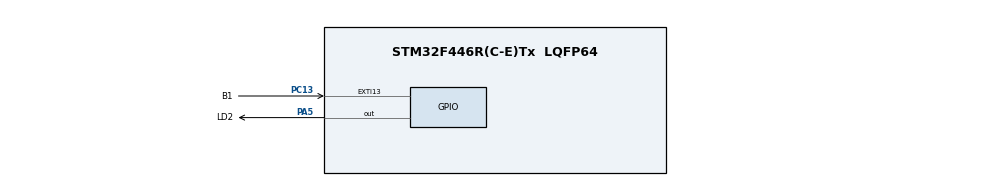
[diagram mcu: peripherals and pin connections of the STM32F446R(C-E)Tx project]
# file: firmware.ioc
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Mcu.Family=STM32F4
Mcu.Name=STM32F446R(C-E)Tx
Mcu.Package=LQFP64
NVIC.EXTI15_10_IRQn=true\:0\:0\:false\:false\:true\:true\:true\:true
NVIC.PriorityGroup=NVIC_PRIORITYGROUP_4
PA5.GPIO_Label=LD2
PA5.Signal=GPIO_Output
PA13.Mode=Serial_Wire
PA13.Signal=SYS_JTMS-SWDIO
PA14.Mode=Serial_Wire
PA14.Signal=SYS_JTCK-SWCLK
PC13.GPIO_Label=B1
PC13.GPIO_ModeDefaultEXTI=GPIO_MODE_IT_FALLING
PC13.GPIO_PuPd=GPIO_NOPULL
PC13.Signal=GPXTI13
PH0-OSC_IN.Mode=HSE-External-Clock-Source
PH0-OSC_IN.Signal=RCC_OSC_IN
PH1-OSC_OUT.Mode=HSE-External-Clock-Source
PH1-OSC_OUT.Signal=RCC_OSC_OUT
ProjectManager.HeapSize=0x200
ProjectManager.StackSize=0x400
ProjectManager.TargetToolchain=STM32CubeIDE
RCC.CortexFreq_Value=16000000
RCC.USBFreq_Value=96000000
RCC.VCOOutputFreq_Value=192000000
SYS.DebugMode=Serial_Wire
board=custom

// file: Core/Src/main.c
/* USER CODE BEGIN Header */
/**
  ******************************************************************************
  * @file           : main.c
  * @brief          : Main program body
  ******************************************************************************
  * @attention
  *
  * Copyright (c) 2026 STMicroelectronics.
  * All rights reserved.
  *
  * This software is licensed under terms that can be found in the LICENSE file
  * in the root directory of this software component.
  * If no LICENSE file comes with this software, it is provided AS-IS.
  *
  ******************************************************************************
  */
/* USER CODE END Header */
#include "main.h"

/* USER CODE BEGIN Includes */
#include "level_check.h"
#include "status_LEDs.h"
#include "pump_control.h"
#include "dose_calc.h"
/* USER CODE END Includes */

void SystemClock_Config(void);
static void MX_GPIO_Init(void);

int main(void)
{

  /* MCU Configuration--------------------------------------------------------*/

  /* Reset of all peripherals, Initializes the Flash interface and the Systick. */
  HAL_Init();

  /* Configure the system clock */
  SystemClock_Config();

  /* Initialize all configured peripherals */
  MX_GPIO_Init();
  /* USER CODE BEGIN 2 */
  level_check_init();
  status_leds_init();
  pump_control_init();
  /* USER CODE END 2 */

  /* Infinite loop */
  while (1)
  {
	  // latches on once the level drops below the refill mark, and only
	  // clears once the tank is actually topped back up to the full mark -
	  // so yellow stays on for the whole refill cycle, not just until the
	  // level ticks back above the refill switch.
	  static bool needs_refill = false;

	  if (tank_is_full())
	  {
		  needs_refill = false;
	  }
	  else if (tank_below_refill())
	  {
		  needs_refill = true;
	  }

	  tank_state_t tank_state;
	  if (tank_is_low())
	  {
		  tank_state = TANK_LOW;
	  }
	  else if (needs_refill)
	  {
		  tank_state = TANK_REFILL;
	  }
	  else
	  {
		  tank_state = TANK_FULL;
	  }
	  tank_leds_set(tank_state);

	  bot1_leds_set(bot1_is_empty() ? BOT_EMPTY : BOT_FULL);
	  bot2_leds_set(bot2_is_empty() ? BOT_EMPTY : BOT_FULL);
	  bot3_leds_set(bot3_is_empty() ? BOT_EMPTY : BOT_FULL);
	  bot4_leds_set(bot4_is_empty() ? BOT_EMPTY : BOT_FULL);

	  pump_control_update();

	  // bench characterization: B1 press starts a test dose on the next
	  // pump in rotation, cycling A->B->C->D->A... so all 4 can be run
	  // without reflashing between them. debounced the same way as the
	  // level switches - sampled once per 50 ms loop pass. TODO: once
	  // dosing is closed-loop, remap B1 to an e-stop instead.
	  static dose_content_t next_test_pump = DOSE_CAL_NITRATE;
	  static bool button_stable = false;
	  static bool button_candidate = false;
	  static uint8_t button_count = 0;

	  bool button_raw = (HAL_GPIO_ReadPin(B1_GPIO_Port, B1_Pin) == GPIO_PIN_RESET);
	  if (button_raw == button_candidate)
	  {
		  if (button_count < 3) button_count++;
	  }
	  else
	  {
		  button_candidate = button_raw;
		  button_count = 1;
	  }

	  bool button_was_stable = button_stable;
	  if (button_count >= 3)
	  {
		  button_stable = button_candidate;
	  }

	  if (button_stable && !button_was_stable) // rising edge = press
	  {
		  // TODO: gate on !tank_is_low() before starting a dose.
		  if (pump_dose_start(next_test_pump, dose_calc_duration_ms(next_test_pump)))
		  {
			  next_test_pump = (next_test_pump + 1) % DOSE_CONTENT_COUNT;
		  }
	  }

	  bool any_pump_running = false;
	  for (int i = 0; i < DOSE_CONTENT_COUNT; i++)
	  {
		  if (pump_is_busy((dose_content_t)i))
		  {
			  any_pump_running = true;
		  }
	  }
	  // TODO: swap system LED to be for errors in the final code
	  sys_leds_set(any_pump_running ? SYS_OK : SYS_OFF); // System LED indicates pump running for debug

	  HAL_Delay(50);
  }
}

void SystemClock_Config(void)
{
  RCC_OscInitTypeDef RCC_OscInitStruct = {0};
  RCC_ClkInitTypeDef RCC_ClkInitStruct = {0};

  /** Configure the main internal regulator output voltage
  */
  __HAL_RCC_PWR_CLK_ENABLE();
  __HAL_PWR_VOLTAGESCALING_CONFIG(PWR_REGULATOR_VOLTAGE_SCALE3);

  /** Initializes the RCC Oscillators according to the specified parameters
  * in the RCC_OscInitTypeDef structure.
  */
  RCC_OscInitStruct.OscillatorType = RCC_OSCILLATORTYPE_HSI;
  RCC_OscInitStruct.HSIState = RCC_HSI_ON;
  RCC_OscInitStruct.HSICalibrationValue = RCC_HSICALIBRATION_DEFAULT;
  RCC_OscInitStruct.PLL.PLLState = RCC_PLL_NONE;
  if (HAL_RCC_OscConfig(&RCC_OscInitStruct) != HAL_OK)
  {
    Error_Handler();
  }

  /** Initializes the CPU, AHB and APB buses clocks
  */
  RCC_ClkInitStruct.ClockType = RCC_CLOCKTYPE_HCLK|RCC_CLOCKTYPE_SYSCLK
                              |RCC_CLOCKTYPE_PCLK1|RCC_CLOCKTYPE_PCLK2;
  RCC_ClkInitStruct.SYSCLKSource = RCC_SYSCLKSOURCE_HSI;
  RCC_ClkInitStruct.AHBCLKDivider = RCC_SYSCLK_DIV1;
  RCC_ClkInitStruct.APB1CLKDivider = RCC_HCLK_DIV1;
  RCC_ClkInitStruct.APB2CLKDivider = RCC_HCLK_DIV1;

  if (HAL_RCC_ClockConfig(&RCC_ClkInitStruct, FLASH_LATENCY_0) != HAL_OK)
  {
    Error_Handler();
  }
}

static void MX_GPIO_Init(void)
{
  GPIO_InitTypeDef GPIO_InitStruct = {0};

  /* GPIO Ports Clock Enable */
  __HAL_RCC_GPIOC_CLK_ENABLE();
  __HAL_RCC_GPIOH_CLK_ENABLE();
  __HAL_RCC_GPIOA_CLK_ENABLE();

  /*Configure GPIO pin Output Level */
  HAL_GPIO_WritePin(LD2_GPIO_Port, LD2_Pin, GPIO_PIN_RESET);

  /*Configure GPIO pin : B1_Pin */
  GPIO_InitStruct.Pin = B1_Pin;
  GPIO_InitStruct.Mode = GPIO_MODE_IT_FALLING;
  GPIO_InitStruct.Pull = GPIO_NOPULL;
  HAL_GPIO_Init(B1_GPIO_Port, &GPIO_InitStruct);

  /*Configure GPIO pin : LD2_Pin */
  GPIO_InitStruct.Pin = LD2_Pin;
  GPIO_InitStruct.Mode = GPIO_MODE_OUTPUT_PP;
  GPIO_InitStruct.Pull = GPIO_NOPULL;
  GPIO_InitStruct.Speed = GPIO_SPEED_FREQ_LOW;
  HAL_GPIO_Init(LD2_GPIO_Port, &GPIO_InitStruct);

  /* EXTI interrupt init*/
  HAL_NVIC_SetPriority(EXTI15_10_IRQn, 0, 0);
  HAL_NVIC_EnableIRQ(EXTI15_10_IRQn);

}

void Error_Handler(void)
{
  __disable_irq();
  while (1)
  {
  }
}
